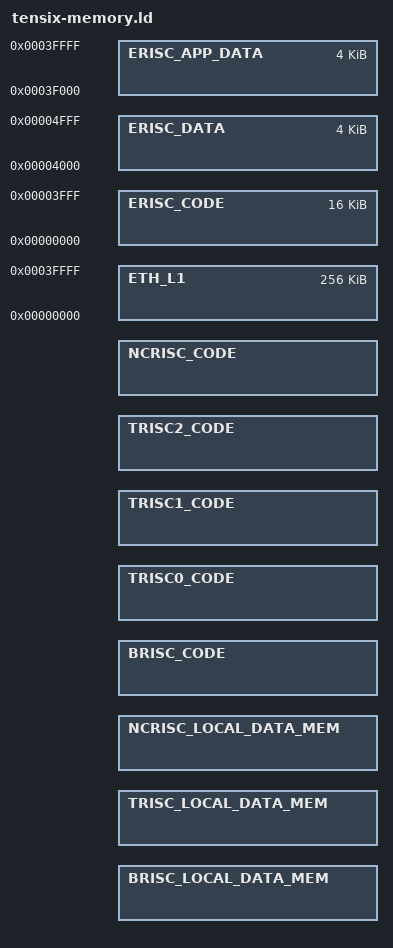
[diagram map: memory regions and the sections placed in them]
MEMORY
{
    BRISC_LOCAL_DATA_MEM : ORIGIN = MEM_LOCAL_BASE, LENGTH = MEM_LOCAL_SIZE
    TRISC_LOCAL_DATA_MEM : ORIGIN = MEM_LOCAL_BASE, LENGTH = MEM_TRISC_LOCAL_SIZE
    NCRISC_LOCAL_DATA_MEM : ORIGIN = MEM_LOCAL_BASE, LENGTH = MEM_LOCAL_SIZE

    BRISC_CODE : ORIGIN = MEM_BRISC_FIRMWARE_BASE, LENGTH = MEM_BRISC_FIRMWARE_SIZE
    TRISC0_CODE : ORIGIN = MEM_TRISC0_BASE, LENGTH = MEM_TRISC0_SIZE
    TRISC1_CODE : ORIGIN = MEM_TRISC1_BASE, LENGTH = MEM_TRISC1_SIZE
    TRISC2_CODE : ORIGIN = MEM_TRISC2_BASE, LENGTH = MEM_TRISC2_SIZE
    NCRISC_CODE : ORIGIN = MEM_NCRISC_IRAM_BASE, LENGTH = MEM_NCRISC_IRAM_SIZE

    ETH_L1 : ORIGIN = 0x00000000, LENGTH = 256K
    ERISC_CODE : ORIGIN = 0x00000000, LENGTH = 16K
    ERISC_DATA : ORIGIN = 0x00004000, LENGTH = 4K
    ERISC_APP_DATA : ORIGIN = 0x0003F000, LENGTH = 4K
}
